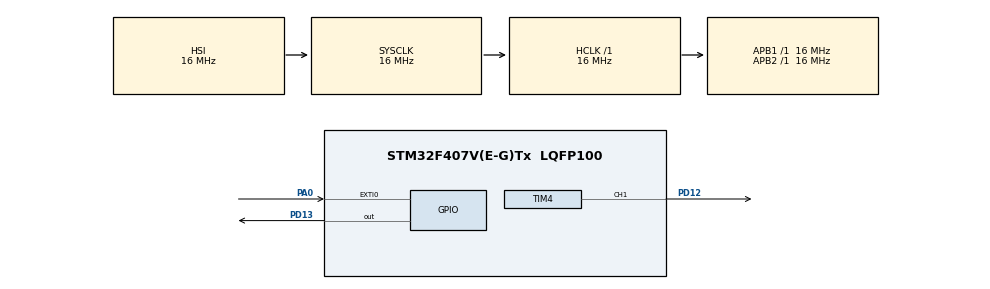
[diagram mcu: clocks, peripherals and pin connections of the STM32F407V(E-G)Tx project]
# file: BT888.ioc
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IWDG.Prescaler=IWDG_PRESCALER_128
IWDG.Reload=2499
Mcu.Family=STM32F4
Mcu.Name=STM32F407V(E-G)Tx
Mcu.Package=LQFP100
NVIC.EXTI0_IRQn=true\:0\:0\:false\:false\:true\:true\:true\:true
NVIC.PriorityGroup=NVIC_PRIORITYGROUP_4
PA0-WKUP.GPIO_ModeDefaultEXTI=GPIO_MODE_IT_RISING
PA0-WKUP.GPIO_PuPd=GPIO_NOPULL
PA0-WKUP.Signal=GPXTI0
PA13.Mode=Serial_Wire
PA13.Signal=SYS_JTMS-SWDIO
PA14.Mode=Serial_Wire
PA14.Signal=SYS_JTCK-SWCLK
PD12.Signal=S_TIM4_CH1
PD13.Signal=GPIO_Output
PH0-OSC_IN.Mode=HSE-External-Oscillator
PH0-OSC_IN.Signal=RCC_OSC_IN
PH1-OSC_OUT.Mode=HSE-External-Oscillator
PH1-OSC_OUT.Signal=RCC_OSC_OUT
ProjectManager.HeapSize=0x200
ProjectManager.StackSize=0x400
ProjectManager.TargetToolchain=STM32CubeIDE
RCC.48MHZClocksFreq_Value=75000000
RCC.AHBFreq_Value=16000000
RCC.APB1Freq_Value=16000000
RCC.APB2Freq_Value=16000000
RCC.CortexFreq_Value=16000000
RCC.HSE_VALUE=25000000
RCC.HSI_VALUE=16000000
RCC.LSE_VALUE=32768
RCC.PLLSourceVirtual=RCC_PLLSOURCE_HSE
RCC.SYSCLKFreq_VALUE=16000000
RCC.VCOOutputFreq_Value=300000000
SH.S_TIM4_CH1.0=TIM4_CH1,PWM Generation1 CH1
TIM4.Channel-PWM\ Generation1\ CH1=TIM_CHANNEL_1
TIM4.Period=1000
TIM4.Prescaler=15
VP_IWDG_VS_IWDG.Mode=IWDG_Activate
VP_TIM4_VS_ClockSourceINT.Mode=Internal
board=custom

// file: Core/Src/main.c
/* USER CODE BEGIN Header */
/**
  ******************************************************************************
  * @file           : main.c
  * @brief          : Main program body
  ******************************************************************************
  * @attention
  *
  * Copyright (c) 2026 STMicroelectronics.
  * All rights reserved.
  *
  * This software is licensed under terms that can be found in the LICENSE file
  * in the root directory of this software component.
  * If no LICENSE file comes with this software, it is provided AS-IS.
  *
  ******************************************************************************
  */
/* USER CODE END Header */
#include "main.h"

/* USER CODE BEGIN PD */
volatile int duty_cycle=0;
uint8_t isUp = 1;
/* USER CODE END PD */

IWDG_HandleTypeDef hiwdg;

TIM_HandleTypeDef htim4;

void SystemClock_Config(void);
static void MX_GPIO_Init(void);
static void MX_TIM4_Init(void);
static void MX_IWDG_Init(void);

/* USER CODE BEGIN 0 */
void HAL_GPIO_EXTI_Callback(uint16_t GPIO_PIN)
{
    if (GPIO_PIN == GPIO_PIN_0)  // Nút nhấn trên PIN 0
    {
        HAL_GPIO_TogglePin(GPIOD, GPIO_PIN_13);
        HAL_IWDG_Refresh(&hiwdg);
        // Tăng duty
        if (isUp == 1)
        {
            if (duty_cycle <= htim4.Init.Period - 100)  // Còn chỗ để tăng
            {
                duty_cycle += 100;
            }
            else
            {
                duty_cycle = htim4.Init.Period;  // Đạt 100%
                isUp = 0;                        // Chuyển sang giảm
            }
        }
        // Giảm duty cycle
        else
        {
            if (duty_cycle >= 100)  // Còn chỗ để giảm
            {
                duty_cycle -= 100;
            }
            else
            {
                duty_cycle = 0;      // Đạt 0%
                isUp = 1;            // Chuyển lại sang tăng
            }
        }

        // Cập nhật PWM với giá trị duty_cycle mới
        __HAL_TIM_SET_COMPARE(&htim4, TIM_CHANNEL_1, duty_cycle);
    }
}
/* USER CODE END 0 */

int main(void)
{

  /* MCU Configuration--------------------------------------------------------*/

  /* Reset of all peripherals, Initializes the Flash interface and the Systick. */
  HAL_Init();

  /* Configure the system clock */
  SystemClock_Config();

  /* Initialize all configured peripherals */
  MX_GPIO_Init();
  MX_TIM4_Init();
  MX_IWDG_Init();
  /* USER CODE BEGIN 2 */
  HAL_TIM_PWM_Start(&htim4, TIM_CHANNEL_1);
  HAL_IWDG_Init(&hiwdg);
  /* USER CODE END 2 */

  /* Infinite loop */
  while (1)
  {

  }
}

void SystemClock_Config(void)
{
  RCC_OscInitTypeDef RCC_OscInitStruct = {0};
  RCC_ClkInitTypeDef RCC_ClkInitStruct = {0};

  /** Configure the main internal regulator output voltage
  */
  __HAL_RCC_PWR_CLK_ENABLE();
  __HAL_PWR_VOLTAGESCALING_CONFIG(PWR_REGULATOR_VOLTAGE_SCALE1);

  /** Initializes the RCC Oscillators according to the specified parameters
  * in the RCC_OscInitTypeDef structure.
  */
  RCC_OscInitStruct.OscillatorType = RCC_OSCILLATORTYPE_HSI|RCC_OSCILLATORTYPE_LSI;
  RCC_OscInitStruct.HSIState = RCC_HSI_ON;
  RCC_OscInitStruct.HSICalibrationValue = RCC_HSICALIBRATION_DEFAULT;
  RCC_OscInitStruct.LSIState = RCC_LSI_ON;
  RCC_OscInitStruct.PLL.PLLState = RCC_PLL_NONE;
  if (HAL_RCC_OscConfig(&RCC_OscInitStruct) != HAL_OK)
  {
    Error_Handler();
  }

  /** Initializes the CPU, AHB and APB buses clocks
  */
  RCC_ClkInitStruct.ClockType = RCC_CLOCKTYPE_HCLK|RCC_CLOCKTYPE_SYSCLK
                              |RCC_CLOCKTYPE_PCLK1|RCC_CLOCKTYPE_PCLK2;
  RCC_ClkInitStruct.SYSCLKSource = RCC_SYSCLKSOURCE_HSI;
  RCC_ClkInitStruct.AHBCLKDivider = RCC_SYSCLK_DIV1;
  RCC_ClkInitStruct.APB1CLKDivider = RCC_HCLK_DIV1;
  RCC_ClkInitStruct.APB2CLKDivider = RCC_HCLK_DIV1;

  if (HAL_RCC_ClockConfig(&RCC_ClkInitStruct, FLASH_LATENCY_0) != HAL_OK)
  {
    Error_Handler();
  }
}

static void MX_IWDG_Init(void)
{

  hiwdg.Instance = IWDG;
  hiwdg.Init.Prescaler = IWDG_PRESCALER_128;
  hiwdg.Init.Reload = 2499;
  if (HAL_IWDG_Init(&hiwdg) != HAL_OK)
  {
    Error_Handler();
  }

}

static void MX_TIM4_Init(void)
{

  TIM_ClockConfigTypeDef sClockSourceConfig = {0};
  TIM_MasterConfigTypeDef sMasterConfig = {0};
  TIM_OC_InitTypeDef sConfigOC = {0};

  htim4.Instance = TIM4;
  htim4.Init.Prescaler = 15;
  htim4.Init.CounterMode = TIM_COUNTERMODE_UP;
  htim4.Init.Period = 1000;
  htim4.Init.ClockDivision = TIM_CLOCKDIVISION_DIV1;
  htim4.Init.AutoReloadPreload = TIM_AUTORELOAD_PRELOAD_DISABLE;
  if (HAL_TIM_Base_Init(&htim4) != HAL_OK)
  {
    Error_Handler();
  }
  sClockSourceConfig.ClockSource = TIM_CLOCKSOURCE_INTERNAL;
  if (HAL_TIM_ConfigClockSource(&htim4, &sClockSourceConfig) != HAL_OK)
  {
    Error_Handler();
  }
  if (HAL_TIM_PWM_Init(&htim4) != HAL_OK)
  {
    Error_Handler();
  }
  sMasterConfig.MasterOutputTrigger = TIM_TRGO_RESET;
  sMasterConfig.MasterSlaveMode = TIM_MASTERSLAVEMODE_DISABLE;
  if (HAL_TIMEx_MasterConfigSynchronization(&htim4, &sMasterConfig) != HAL_OK)
  {
    Error_Handler();
  }
  sConfigOC.OCMode = TIM_OCMODE_PWM1;
  sConfigOC.Pulse = 0;
  sConfigOC.OCPolarity = TIM_OCPOLARITY_HIGH;
  sConfigOC.OCFastMode = TIM_OCFAST_DISABLE;
  if (HAL_TIM_PWM_ConfigChannel(&htim4, &sConfigOC, TIM_CHANNEL_1) != HAL_OK)
  {
    Error_Handler();
  }
  HAL_TIM_MspPostInit(&htim4);

}

static void MX_GPIO_Init(void)
{
  GPIO_InitTypeDef GPIO_InitStruct = {0};

  /* GPIO Ports Clock Enable */
  __HAL_RCC_GPIOH_CLK_ENABLE();
  __HAL_RCC_GPIOA_CLK_ENABLE();
  __HAL_RCC_GPIOD_CLK_ENABLE();

  /*Configure GPIO pin Output Level */
  HAL_GPIO_WritePin(GPIOD, GPIO_PIN_13, GPIO_PIN_RESET);

  /*Configure GPIO pin : PA0 */
  GPIO_InitStruct.Pin = GPIO_PIN_0;
  GPIO_InitStruct.Mode = GPIO_MODE_IT_RISING;
  GPIO_InitStruct.Pull = GPIO_NOPULL;
  HAL_GPIO_Init(GPIOA, &GPIO_InitStruct);

  /*Configure GPIO pin : PD13 */
  GPIO_InitStruct.Pin = GPIO_PIN_13;
  GPIO_InitStruct.Mode = GPIO_MODE_OUTPUT_PP;
  GPIO_InitStruct.Pull = GPIO_NOPULL;
  GPIO_InitStruct.Speed = GPIO_SPEED_FREQ_LOW;
  HAL_GPIO_Init(GPIOD, &GPIO_InitStruct);

  /* EXTI interrupt init*/
  HAL_NVIC_SetPriority(EXTI0_IRQn, 0, 0);
  HAL_NVIC_EnableIRQ(EXTI0_IRQn);

}

void Error_Handler(void)
{
  __disable_irq();
  while (1)
  {
  }
}
